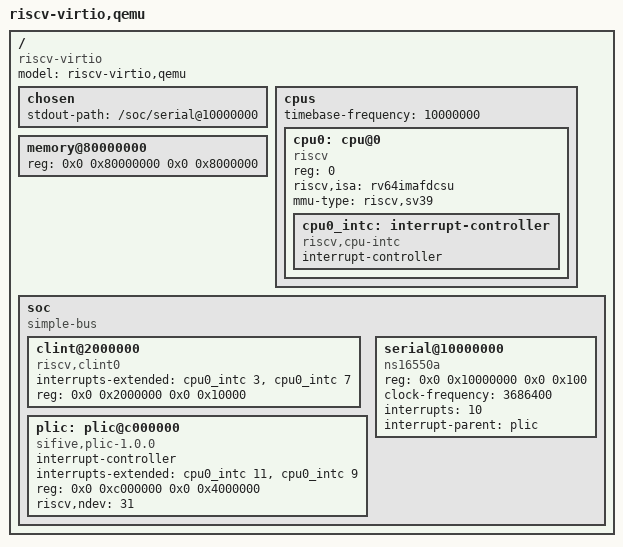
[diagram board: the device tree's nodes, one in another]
/dts-v1/;

/ {
    #address-cells = <2>;
    #size-cells = <2>;
    compatible = "riscv-virtio";
    model = "riscv-virtio,qemu";

    chosen {
        stdout-path = "/soc/serial@10000000";
    };

    cpus {
        #address-cells = <1>;
        #size-cells = <0>;
        timebase-frequency = <10000000>;

        cpu0: cpu@0 {
            device_type = "cpu";
            reg = <0>;
            status = "okay";
            compatible = "riscv";
            riscv,isa = "rv64imafdcsu";
            mmu-type = "riscv,sv39";

            cpu0_intc: interrupt-controller {
                #interrupt-cells = <1>;
                interrupt-controller;
                compatible = "riscv,cpu-intc";
            };
        };
    };

    memory@80000000 {
        device_type = "memory";
        reg = <0x0 0x80000000 0x0 0x8000000>;
    };

    soc {
        #address-cells = <2>;
        #size-cells = <2>;
        compatible = "simple-bus";
        ranges;

        clint@2000000 {
            compatible = "riscv,clint0";
            interrupts-extended = <&cpu0_intc 3 &cpu0_intc 7>;
            reg = <0x0 0x2000000 0x0 0x10000>;
        };

        plic: plic@c000000 {
            compatible = "sifive,plic-1.0.0", "riscv,plic0";
            #interrupt-cells = <1>;
            interrupt-controller;
            interrupts-extended = <&cpu0_intc 11 &cpu0_intc 9>;
            reg = <0x0 0xc000000 0x0 0x4000000>;
            riscv,ndev = <31>;
        };

        serial@10000000 {
            compatible = "ns16550a";
            reg = <0x0 0x10000000 0x0 0x100>;
            clock-frequency = <3686400>;
            interrupts = <10>;
            interrupt-parent = <&plic>;
        };
    };
};
